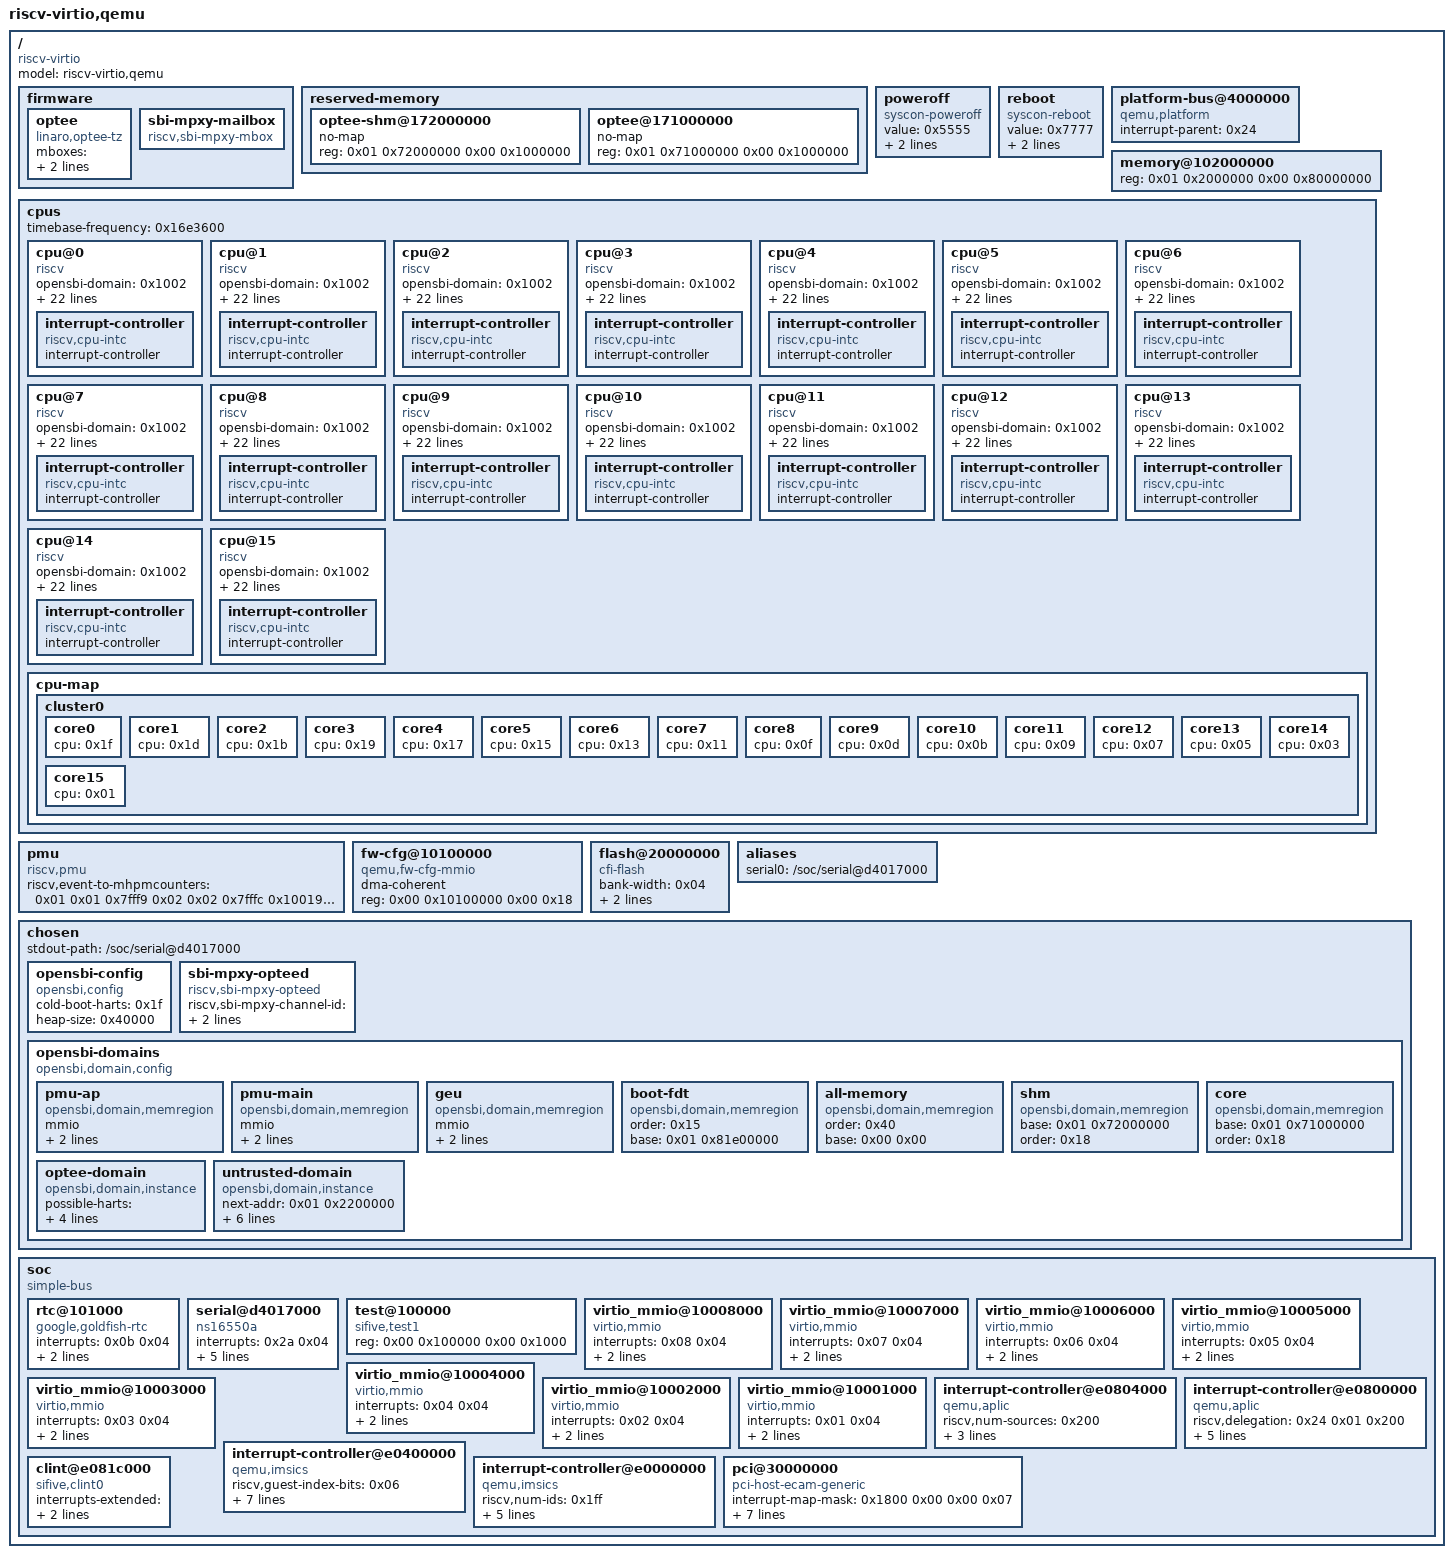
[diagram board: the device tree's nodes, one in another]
/dts-v1/;
/* QEMU jupiter2, 16 harts, 2 GiB. OP-TEE and Linux OpenSBI domains. */

/ {
	#address-cells = <0x02>;
	#size-cells = <0x02>;
	compatible = "riscv-virtio";
	model = "riscv-virtio,qemu";

	firmware {

		optee {
			mboxes = <0x1014 0x1000 0x02 0x1014 0x1001 0x02 0x1014 0x1002 0x02 0x1014 0x1003 0x02 0x1014 0x1004 0x02 0x1014 0x1005 0x02 0x1014 0x1006 0x02 0x1014 0x1007 0x02 0x1014 0x1008 0x02 0x1014 0x1009 0x02 0x1014 0x100a 0x02 0x1014 0x100b 0x02 0x1014 0x100c 0x02 0x1014 0x100d 0x02 0x1014 0x100e 0x02 0x1014 0x100f 0x02>;
			method = "smc";
			compatible = "linaro,optee-tz";
		};

		sbi-mpxy-mailbox {
			#mbox-cells = <0x02>;
			phandle = <0x1014>;
			compatible = "riscv,sbi-mpxy-mbox";
		};
	};

	reserved-memory {
		ranges;
		#size-cells = <0x02>;
		#address-cells = <0x02>;

		optee-shm@172000000 {
			no-map;
			reg = <0x01 0x72000000 0x00 0x1000000>;
		};

		optee@171000000 {
			no-map;
			reg = <0x01 0x71000000 0x00 0x1000000>;
		};
	};

	poweroff {
		value = <0x5555>;
		offset = <0x00>;
		regmap = <0x25>;
		compatible = "syscon-poweroff";
	};

	reboot {
		value = <0x7777>;
		offset = <0x00>;
		regmap = <0x25>;
		compatible = "syscon-reboot";
	};

	platform-bus@4000000 {
		interrupt-parent = <0x24>;
		ranges = <0x00 0x00 0x4000000 0x2000000>;
		#address-cells = <0x01>;
		#size-cells = <0x01>;
		compatible = "qemu,platform", "simple-bus";
	};

	memory@102000000 {
		device_type = "memory";
		reg = <0x01 0x2000000 0x00 0x80000000>;
	};

	cpus {
		#address-cells = <0x01>;
		#size-cells = <0x00>;
		timebase-frequency = <0x16e3600>;

		cpu@0 {
			opensbi-domain = <0x1002>;
			phandle = <0x1f>;
			device_type = "cpu";
			reg = <0x00>;
			status = "okay";
			compatible = "riscv";
			riscv,cbop-block-size = <0x40>;
			riscv,cboz-block-size = <0x40>;
			riscv,cbom-block-size = <0x40>;
			riscv,isa-extensions = "i", "m", "a", "f", "d", "c", "b", "v", "h", "zic64b", "zicbom", "zicbop", "zicboz", "ziccamoa", "ziccif", "zicclsm", "ziccrse", "zicond", "zicntr", "zicsr", "zifencei", "zihintntl", "zihintpause", "zihpm", "zimop", "zmmul", "za64rs", "zaamo", "zalrsc", "zawrs", "zfa", "zfhmin", "zca", "zcb", "zcd", "zcmop", "zba", "zbb", "zbs", "zkt", "zvbb", "zve32f", "zve32x", "zve64f", "zve64d", "zve64x", "zvfhmin", "zvkb", "zvkt", "sdtrig", "shcounterenw", "sha", "shgatpa", "shtvala", "shvsatpa", "shvstvala", "shvstvecd", "smaia", "smnpm", "smstateen", "ssaia", "ssccptr", "sscofpmf", "sscounterenw", "ssnpm", "ssstateen", "ssstrict", "sstc", "sstvala", "sstvecd", "ssu64xl", "supm", "svade", "svinval", "svnapot", "svpbmt";
			riscv,isa-base = "rv64i";
			riscv,isa = "rv64imafdcbvh_zic64b_zicbom_zicbop_zicboz_ziccamoa_ziccif_zicclsm_ziccrse_zicond_zicntr_zicsr_zifencei_zihintntl_zihintpause_zihpm_zimop_zmmul_za64rs_zaamo_zalrsc_zawrs_zfa_zfhmin_zca_zcb_zcd_zcmop_zba_zbb_zbs_zkt_zvbb_zve32f_zve32x_zve64f_zve64d_zve64x_zvfhmin_zvkb_zvkt_sdtrig_shcounterenw_sha_shgatpa_shtvala_shvsatpa_shvstvala_shvstvecd_smaia_smnpm_smstateen_ssaia_ssccptr_sscofpmf_sscounterenw_ssnpm_ssstateen_ssstrict_sstc_sstvala_sstvecd_ssu64xl_supm_svade_svinval_svnapot_svpbmt";
			mmu-type = "riscv,sv39";

			interrupt-controller {
				#interrupt-cells = <0x01>;
				interrupt-controller;
				compatible = "riscv,cpu-intc";
				phandle = <0x20>;
			};
		};

		cpu@1 {
			opensbi-domain = <0x1002>;
			phandle = <0x1d>;
			device_type = "cpu";
			reg = <0x01>;
			status = "okay";
			compatible = "riscv";
			riscv,cbop-block-size = <0x40>;
			riscv,cboz-block-size = <0x40>;
			riscv,cbom-block-size = <0x40>;
			riscv,isa-extensions = "i", "m", "a", "f", "d", "c", "b", "v", "h", "zic64b", "zicbom", "zicbop", "zicboz", "ziccamoa", "ziccif", "zicclsm", "ziccrse", "zicond", "zicntr", "zicsr", "zifencei", "zihintntl", "zihintpause", "zihpm", "zimop", "zmmul", "za64rs", "zaamo", "zalrsc", "zawrs", "zfa", "zfhmin", "zca", "zcb", "zcd", "zcmop", "zba", "zbb", "zbs", "zkt", "zvbb", "zve32f", "zve32x", "zve64f", "zve64d", "zve64x", "zvfhmin", "zvkb", "zvkt", "sdtrig", "shcounterenw", "sha", "shgatpa", "shtvala", "shvsatpa", "shvstvala", "shvstvecd", "smaia", "smnpm", "smstateen", "ssaia", "ssccptr", "sscofpmf", "sscounterenw", "ssnpm", "ssstateen", "ssstrict", "sstc", "sstvala", "sstvecd", "ssu64xl", "supm", "svade", "svinval", "svnapot", "svpbmt";
			riscv,isa-base = "rv64i";
			riscv,isa = "rv64imafdcbvh_zic64b_zicbom_zicbop_zicboz_ziccamoa_ziccif_zicclsm_ziccrse_zicond_zicntr_zicsr_zifencei_zihintntl_zihintpause_zihpm_zimop_zmmul_za64rs_zaamo_zalrsc_zawrs_zfa_zfhmin_zca_zcb_zcd_zcmop_zba_zbb_zbs_zkt_zvbb_zve32f_zve32x_zve64f_zve64d_zve64x_zvfhmin_zvkb_zvkt_sdtrig_shcounterenw_sha_shgatpa_shtvala_shvsatpa_shvstvala_shvstvecd_smaia_smnpm_smstateen_ssaia_ssccptr_sscofpmf_sscounterenw_ssnpm_ssstateen_ssstrict_sstc_sstvala_sstvecd_ssu64xl_supm_svade_svinval_svnapot_svpbmt";
			mmu-type = "riscv,sv39";

			interrupt-controller {
				#interrupt-cells = <0x01>;
				interrupt-controller;
				compatible = "riscv,cpu-intc";
				phandle = <0x1e>;
			};
		};

		cpu@2 {
			opensbi-domain = <0x1002>;
			phandle = <0x1b>;
			device_type = "cpu";
			reg = <0x02>;
			status = "okay";
			compatible = "riscv";
			riscv,cbop-block-size = <0x40>;
			riscv,cboz-block-size = <0x40>;
			riscv,cbom-block-size = <0x40>;
			riscv,isa-extensions = "i", "m", "a", "f", "d", "c", "b", "v", "h", "zic64b", "zicbom", "zicbop", "zicboz", "ziccamoa", "ziccif", "zicclsm", "ziccrse", "zicond", "zicntr", "zicsr", "zifencei", "zihintntl", "zihintpause", "zihpm", "zimop", "zmmul", "za64rs", "zaamo", "zalrsc", "zawrs", "zfa", "zfhmin", "zca", "zcb", "zcd", "zcmop", "zba", "zbb", "zbs", "zkt", "zvbb", "zve32f", "zve32x", "zve64f", "zve64d", "zve64x", "zvfhmin", "zvkb", "zvkt", "sdtrig", "shcounterenw", "sha", "shgatpa", "shtvala", "shvsatpa", "shvstvala", "shvstvecd", "smaia", "smnpm", "smstateen", "ssaia", "ssccptr", "sscofpmf", "sscounterenw", "ssnpm", "ssstateen", "ssstrict", "sstc", "sstvala", "sstvecd", "ssu64xl", "supm", "svade", "svinval", "svnapot", "svpbmt";
			riscv,isa-base = "rv64i";
			riscv,isa = "rv64imafdcbvh_zic64b_zicbom_zicbop_zicboz_ziccamoa_ziccif_zicclsm_ziccrse_zicond_zicntr_zicsr_zifencei_zihintntl_zihintpause_zihpm_zimop_zmmul_za64rs_zaamo_zalrsc_zawrs_zfa_zfhmin_zca_zcb_zcd_zcmop_zba_zbb_zbs_zkt_zvbb_zve32f_zve32x_zve64f_zve64d_zve64x_zvfhmin_zvkb_zvkt_sdtrig_shcounterenw_sha_shgatpa_shtvala_shvsatpa_shvstvala_shvstvecd_smaia_smnpm_smstateen_ssaia_ssccptr_sscofpmf_sscounterenw_ssnpm_ssstateen_ssstrict_sstc_sstvala_sstvecd_ssu64xl_supm_svade_svinval_svnapot_svpbmt";
			mmu-type = "riscv,sv39";

			interrupt-controller {
				#interrupt-cells = <0x01>;
				interrupt-controller;
				compatible = "riscv,cpu-intc";
				phandle = <0x1c>;
			};
		};

		cpu@3 {
			opensbi-domain = <0x1002>;
			phandle = <0x19>;
			device_type = "cpu";
			reg = <0x03>;
			status = "okay";
			compatible = "riscv";
			riscv,cbop-block-size = <0x40>;
			riscv,cboz-block-size = <0x40>;
			riscv,cbom-block-size = <0x40>;
			riscv,isa-extensions = "i", "m", "a", "f", "d", "c", "b", "v", "h", "zic64b", "zicbom", "zicbop", "zicboz", "ziccamoa", "ziccif", "zicclsm", "ziccrse", "zicond", "zicntr", "zicsr", "zifencei", "zihintntl", "zihintpause", "zihpm", "zimop", "zmmul", "za64rs", "zaamo", "zalrsc", "zawrs", "zfa", "zfhmin", "zca", "zcb", "zcd", "zcmop", "zba", "zbb", "zbs", "zkt", "zvbb", "zve32f", "zve32x", "zve64f", "zve64d", "zve64x", "zvfhmin", "zvkb", "zvkt", "sdtrig", "shcounterenw", "sha", "shgatpa", "shtvala", "shvsatpa", "shvstvala", "shvstvecd", "smaia", "smnpm", "smstateen", "ssaia", "ssccptr", "sscofpmf", "sscounterenw", "ssnpm", "ssstateen", "ssstrict", "sstc", "sstvala", "sstvecd", "ssu64xl", "supm", "svade", "svinval", "svnapot", "svpbmt";
			riscv,isa-base = "rv64i";
			riscv,isa = "rv64imafdcbvh_zic64b_zicbom_zicbop_zicboz_ziccamoa_ziccif_zicclsm_ziccrse_zicond_zicntr_zicsr_zifencei_zihintntl_zihintpause_zihpm_zimop_zmmul_za64rs_zaamo_zalrsc_zawrs_zfa_zfhmin_zca_zcb_zcd_zcmop_zba_zbb_zbs_zkt_zvbb_zve32f_zve32x_zve64f_zve64d_zve64x_zvfhmin_zvkb_zvkt_sdtrig_shcounterenw_sha_shgatpa_shtvala_shvsatpa_shvstvala_shvstvecd_smaia_smnpm_smstateen_ssaia_ssccptr_sscofpmf_sscounterenw_ssnpm_ssstateen_ssstrict_sstc_sstvala_sstvecd_ssu64xl_supm_svade_svinval_svnapot_svpbmt";
			mmu-type = "riscv,sv39";

			interrupt-controller {
				#interrupt-cells = <0x01>;
				interrupt-controller;
				compatible = "riscv,cpu-intc";
				phandle = <0x1a>;
			};
		};

		cpu@4 {
			opensbi-domain = <0x1002>;
			phandle = <0x17>;
			device_type = "cpu";
			reg = <0x04>;
			status = "okay";
			compatible = "riscv";
			riscv,cbop-block-size = <0x40>;
			riscv,cboz-block-size = <0x40>;
			riscv,cbom-block-size = <0x40>;
			riscv,isa-extensions = "i", "m", "a", "f", "d", "c", "b", "v", "h", "zic64b", "zicbom", "zicbop", "zicboz", "ziccamoa", "ziccif", "zicclsm", "ziccrse", "zicond", "zicntr", "zicsr", "zifencei", "zihintntl", "zihintpause", "zihpm", "zimop", "zmmul", "za64rs", "zaamo", "zalrsc", "zawrs", "zfa", "zfhmin", "zca", "zcb", "zcd", "zcmop", "zba", "zbb", "zbs", "zkt", "zvbb", "zve32f", "zve32x", "zve64f", "zve64d", "zve64x", "zvfhmin", "zvkb", "zvkt", "sdtrig", "shcounterenw", "sha", "shgatpa", "shtvala", "shvsatpa", "shvstvala", "shvstvecd", "smaia", "smnpm", "smstateen", "ssaia", "ssccptr", "sscofpmf", "sscounterenw", "ssnpm", "ssstateen", "ssstrict", "sstc", "sstvala", "sstvecd", "ssu64xl", "supm", "svade", "svinval", "svnapot", "svpbmt";
			riscv,isa-base = "rv64i";
			riscv,isa = "rv64imafdcbvh_zic64b_zicbom_zicbop_zicboz_ziccamoa_ziccif_zicclsm_ziccrse_zicond_zicntr_zicsr_zifencei_zihintntl_zihintpause_zihpm_zimop_zmmul_za64rs_zaamo_zalrsc_zawrs_zfa_zfhmin_zca_zcb_zcd_zcmop_zba_zbb_zbs_zkt_zvbb_zve32f_zve32x_zve64f_zve64d_zve64x_zvfhmin_zvkb_zvkt_sdtrig_shcounterenw_sha_shgatpa_shtvala_shvsatpa_shvstvala_shvstvecd_smaia_smnpm_smstateen_ssaia_ssccptr_sscofpmf_sscounterenw_ssnpm_ssstateen_ssstrict_sstc_sstvala_sstvecd_ssu64xl_supm_svade_svinval_svnapot_svpbmt";
			mmu-type = "riscv,sv39";

			interrupt-controller {
				#interrupt-cells = <0x01>;
				interrupt-controller;
				compatible = "riscv,cpu-intc";
				phandle = <0x18>;
			};
		};

		cpu@5 {
			opensbi-domain = <0x1002>;
			phandle = <0x15>;
			device_type = "cpu";
			reg = <0x05>;
			status = "okay";
			compatible = "riscv";
			riscv,cbop-block-size = <0x40>;
			riscv,cboz-block-size = <0x40>;
			riscv,cbom-block-size = <0x40>;
			riscv,isa-extensions = "i", "m", "a", "f", "d", "c", "b", "v", "h", "zic64b", "zicbom", "zicbop", "zicboz", "ziccamoa", "ziccif", "zicclsm", "ziccrse", "zicond", "zicntr", "zicsr", "zifencei", "zihintntl", "zihintpause", "zihpm", "zimop", "zmmul", "za64rs", "zaamo", "zalrsc", "zawrs", "zfa", "zfhmin", "zca", "zcb", "zcd", "zcmop", "zba", "zbb", "zbs", "zkt", "zvbb", "zve32f", "zve32x", "zve64f", "zve64d", "zve64x", "zvfhmin", "zvkb", "zvkt", "sdtrig", "shcounterenw", "sha", "shgatpa", "shtvala", "shvsatpa", "shvstvala", "shvstvecd", "smaia", "smnpm", "smstateen", "ssaia", "ssccptr", "sscofpmf", "sscounterenw", "ssnpm", "ssstateen", "ssstrict", "sstc", "sstvala", "sstvecd", "ssu64xl", "supm", "svade", "svinval", "svnapot", "svpbmt";
			riscv,isa-base = "rv64i";
			riscv,isa = "rv64imafdcbvh_zic64b_zicbom_zicbop_zicboz_ziccamoa_ziccif_zicclsm_ziccrse_zicond_zicntr_zicsr_zifencei_zihintntl_zihintpause_zihpm_zimop_zmmul_za64rs_zaamo_zalrsc_zawrs_zfa_zfhmin_zca_zcb_zcd_zcmop_zba_zbb_zbs_zkt_zvbb_zve32f_zve32x_zve64f_zve64d_zve64x_zvfhmin_zvkb_zvkt_sdtrig_shcounterenw_sha_shgatpa_shtvala_shvsatpa_shvstvala_shvstvecd_smaia_smnpm_smstateen_ssaia_ssccptr_sscofpmf_sscounterenw_ssnpm_ssstateen_ssstrict_sstc_sstvala_sstvecd_ssu64xl_supm_svade_svinval_svnapot_svpbmt";
			mmu-type = "riscv,sv39";

			interrupt-controller {
				#interrupt-cells = <0x01>;
				interrupt-controller;
				compatible = "riscv,cpu-intc";
				phandle = <0x16>;
			};
		};

		cpu@6 {
			opensbi-domain = <0x1002>;
			phandle = <0x13>;
			device_type = "cpu";
			reg = <0x06>;
			status = "okay";
			compatible = "riscv";
			riscv,cbop-block-size = <0x40>;
			riscv,cboz-block-size = <0x40>;
			riscv,cbom-block-size = <0x40>;
			riscv,isa-extensions = "i", "m", "a", "f", "d", "c", "b", "v", "h", "zic64b", "zicbom", "zicbop", "zicboz", "ziccamoa", "ziccif", "zicclsm", "ziccrse", "zicond", "zicntr", "zicsr", "zifencei", "zihintntl", "zihintpause", "zihpm", "zimop", "zmmul", "za64rs", "zaamo", "zalrsc", "zawrs", "zfa", "zfhmin", "zca", "zcb", "zcd", "zcmop", "zba", "zbb", "zbs", "zkt", "zvbb", "zve32f", "zve32x", "zve64f", "zve64d", "zve64x", "zvfhmin", "zvkb", "zvkt", "sdtrig", "shcounterenw", "sha", "shgatpa", "shtvala", "shvsatpa", "shvstvala", "shvstvecd", "smaia", "smnpm", "smstateen", "ssaia", "ssccptr", "sscofpmf", "sscounterenw", "ssnpm", "ssstateen", "ssstrict", "sstc", "sstvala", "sstvecd", "ssu64xl", "supm", "svade", "svinval", "svnapot", "svpbmt";
			riscv,isa-base = "rv64i";
			riscv,isa = "rv64imafdcbvh_zic64b_zicbom_zicbop_zicboz_ziccamoa_ziccif_zicclsm_ziccrse_zicond_zicntr_zicsr_zifencei_zihintntl_zihintpause_zihpm_zimop_zmmul_za64rs_zaamo_zalrsc_zawrs_zfa_zfhmin_zca_zcb_zcd_zcmop_zba_zbb_zbs_zkt_zvbb_zve32f_zve32x_zve64f_zve64d_zve64x_zvfhmin_zvkb_zvkt_sdtrig_shcounterenw_sha_shgatpa_shtvala_shvsatpa_shvstvala_shvstvecd_smaia_smnpm_smstateen_ssaia_ssccptr_sscofpmf_sscounterenw_ssnpm_ssstateen_ssstrict_sstc_sstvala_sstvecd_ssu64xl_supm_svade_svinval_svnapot_svpbmt";
			mmu-type = "riscv,sv39";

			interrupt-controller {
				#interrupt-cells = <0x01>;
				interrupt-controller;
				compatible = "riscv,cpu-intc";
				phandle = <0x14>;
			};
		};

		cpu@7 {
			opensbi-domain = <0x1002>;
			phandle = <0x11>;
			device_type = "cpu";
			reg = <0x07>;
			status = "okay";
			compatible = "riscv";
			riscv,cbop-block-size = <0x40>;
			riscv,cboz-block-size = <0x40>;
			riscv,cbom-block-size = <0x40>;
			riscv,isa-extensions = "i", "m", "a", "f", "d", "c", "b", "v", "h", "zic64b", "zicbom", "zicbop", "zicboz", "ziccamoa", "ziccif", "zicclsm", "ziccrse", "zicond", "zicntr", "zicsr", "zifencei", "zihintntl", "zihintpause", "zihpm", "zimop", "zmmul", "za64rs", "zaamo", "zalrsc", "zawrs", "zfa", "zfhmin", "zca", "zcb", "zcd", "zcmop", "zba", "zbb", "zbs", "zkt", "zvbb", "zve32f", "zve32x", "zve64f", "zve64d", "zve64x", "zvfhmin", "zvkb", "zvkt", "sdtrig", "shcounterenw", "sha", "shgatpa", "shtvala", "shvsatpa", "shvstvala", "shvstvecd", "smaia", "smnpm", "smstateen", "ssaia", "ssccptr", "sscofpmf", "sscounterenw", "ssnpm", "ssstateen", "ssstrict", "sstc", "sstvala", "sstvecd", "ssu64xl", "supm", "svade", "svinval", "svnapot", "svpbmt";
			riscv,isa-base = "rv64i";
			riscv,isa = "rv64imafdcbvh_zic64b_zicbom_zicbop_zicboz_ziccamoa_ziccif_zicclsm_ziccrse_zicond_zicntr_zicsr_zifencei_zihintntl_zihintpause_zihpm_zimop_zmmul_za64rs_zaamo_zalrsc_zawrs_zfa_zfhmin_zca_zcb_zcd_zcmop_zba_zbb_zbs_zkt_zvbb_zve32f_zve32x_zve64f_zve64d_zve64x_zvfhmin_zvkb_zvkt_sdtrig_shcounterenw_sha_shgatpa_shtvala_shvsatpa_shvstvala_shvstvecd_smaia_smnpm_smstateen_ssaia_ssccptr_sscofpmf_sscounterenw_ssnpm_ssstateen_ssstrict_sstc_sstvala_sstvecd_ssu64xl_supm_svade_svinval_svnapot_svpbmt";
			mmu-type = "riscv,sv39";

			interrupt-controller {
				#interrupt-cells = <0x01>;
				interrupt-controller;
				compatible = "riscv,cpu-intc";
				phandle = <0x12>;
			};
		};

		cpu@8 {
			opensbi-domain = <0x1002>;
			phandle = <0x0f>;
			device_type = "cpu";
			reg = <0x08>;
			status = "okay";
			compatible = "riscv";
			riscv,cbop-block-size = <0x40>;
			riscv,cboz-block-size = <0x40>;
			riscv,cbom-block-size = <0x40>;
			riscv,isa-extensions = "i", "m", "a", "f", "d", "c", "b", "v", "h", "zic64b", "zicbom", "zicbop", "zicboz", "ziccamoa", "ziccif", "zicclsm", "ziccrse", "zicond", "zicntr", "zicsr", "zifencei", "zihintntl", "zihintpause", "zihpm", "zimop", "zmmul", "za64rs", "zaamo", "zalrsc", "zawrs", "zfa", "zfhmin", "zca", "zcb", "zcd", "zcmop", "zba", "zbb", "zbs", "zkt", "zvbb", "zve32f", "zve32x", "zve64f", "zve64d", "zve64x", "zvfhmin", "zvkb", "zvkt", "sdtrig", "shcounterenw", "sha", "shgatpa", "shtvala", "shvsatpa", "shvstvala", "shvstvecd", "smaia", "smnpm", "smstateen", "ssaia", "ssccptr", "sscofpmf", "sscounterenw", "ssnpm", "ssstateen", "ssstrict", "sstc", "sstvala", "sstvecd", "ssu64xl", "supm", "svade", "svinval", "svnapot", "svpbmt";
			riscv,isa-base = "rv64i";
			riscv,isa = "rv64imafdcbvh_zic64b_zicbom_zicbop_zicboz_ziccamoa_ziccif_zicclsm_ziccrse_zicond_zicntr_zicsr_zifencei_zihintntl_zihintpause_zihpm_zimop_zmmul_za64rs_zaamo_zalrsc_zawrs_zfa_zfhmin_zca_zcb_zcd_zcmop_zba_zbb_zbs_zkt_zvbb_zve32f_zve32x_zve64f_zve64d_zve64x_zvfhmin_zvkb_zvkt_sdtrig_shcounterenw_sha_shgatpa_shtvala_shvsatpa_shvstvala_shvstvecd_smaia_smnpm_smstateen_ssaia_ssccptr_sscofpmf_sscounterenw_ssnpm_ssstateen_ssstrict_sstc_sstvala_sstvecd_ssu64xl_supm_svade_svinval_svnapot_svpbmt";
			mmu-type = "riscv,sv39";

			interrupt-controller {
				#interrupt-cells = <0x01>;
				interrupt-controller;
				compatible = "riscv,cpu-intc";
				phandle = <0x10>;
			};
		};

		cpu@9 {
			opensbi-domain = <0x1002>;
			phandle = <0x0d>;
			device_type = "cpu";
			reg = <0x09>;
			status = "okay";
			compatible = "riscv";
			riscv,cbop-block-size = <0x40>;
			riscv,cboz-block-size = <0x40>;
			riscv,cbom-block-size = <0x40>;
			riscv,isa-extensions = "i", "m", "a", "f", "d", "c", "b", "v", "h", "zic64b", "zicbom", "zicbop", "zicboz", "ziccamoa", "ziccif", "zicclsm", "ziccrse", "zicond", "zicntr", "zicsr", "zifencei", "zihintntl", "zihintpause", "zihpm", "zimop", "zmmul", "za64rs", "zaamo", "zalrsc", "zawrs", "zfa", "zfhmin", "zca", "zcb", "zcd", "zcmop", "zba", "zbb", "zbs", "zkt", "zvbb", "zve32f", "zve32x", "zve64f", "zve64d", "zve64x", "zvfhmin", "zvkb", "zvkt", "sdtrig", "shcounterenw", "sha", "shgatpa", "shtvala", "shvsatpa", "shvstvala", "shvstvecd", "smaia", "smnpm", "smstateen", "ssaia", "ssccptr", "sscofpmf", "sscounterenw", "ssnpm", "ssstateen", "ssstrict", "sstc", "sstvala", "sstvecd", "ssu64xl", "supm", "svade", "svinval", "svnapot", "svpbmt";
			riscv,isa-base = "rv64i";
			riscv,isa = "rv64imafdcbvh_zic64b_zicbom_zicbop_zicboz_ziccamoa_ziccif_zicclsm_ziccrse_zicond_zicntr_zicsr_zifencei_zihintntl_zihintpause_zihpm_zimop_zmmul_za64rs_zaamo_zalrsc_zawrs_zfa_zfhmin_zca_zcb_zcd_zcmop_zba_zbb_zbs_zkt_zvbb_zve32f_zve32x_zve64f_zve64d_zve64x_zvfhmin_zvkb_zvkt_sdtrig_shcounterenw_sha_shgatpa_shtvala_shvsatpa_shvstvala_shvstvecd_smaia_smnpm_smstateen_ssaia_ssccptr_sscofpmf_sscounterenw_ssnpm_ssstateen_ssstrict_sstc_sstvala_sstvecd_ssu64xl_supm_svade_svinval_svnapot_svpbmt";
			mmu-type = "riscv,sv39";

			interrupt-controller {
				#interrupt-cells = <0x01>;
				interrupt-controller;
				compatible = "riscv,cpu-intc";
				phandle = <0x0e>;
			};
		};

		cpu@10 {
			opensbi-domain = <0x1002>;
			phandle = <0x0b>;
			device_type = "cpu";
			reg = <0x0a>;
			status = "okay";
			compatible = "riscv";
			riscv,cbop-block-size = <0x40>;
			riscv,cboz-block-size = <0x40>;
			riscv,cbom-block-size = <0x40>;
			riscv,isa-extensions = "i", "m", "a", "f", "d", "c", "b", "v", "h", "zic64b", "zicbom", "zicbop", "zicboz", "ziccamoa", "ziccif", "zicclsm", "ziccrse", "zicond", "zicntr", "zicsr", "zifencei", "zihintntl", "zihintpause", "zihpm", "zimop", "zmmul", "za64rs", "zaamo", "zalrsc", "zawrs", "zfa", "zfhmin", "zca", "zcb", "zcd", "zcmop", "zba", "zbb", "zbs", "zkt", "zvbb", "zve32f", "zve32x", "zve64f", "zve64d", "zve64x", "zvfhmin", "zvkb", "zvkt", "sdtrig", "shcounterenw", "sha", "shgatpa", "shtvala", "shvsatpa", "shvstvala", "shvstvecd", "smaia", "smnpm", "smstateen", "ssaia", "ssccptr", "sscofpmf", "sscounterenw", "ssnpm", "ssstateen", "ssstrict", "sstc", "sstvala", "sstvecd", "ssu64xl", "supm", "svade", "svinval", "svnapot", "svpbmt";
			riscv,isa-base = "rv64i";
			riscv,isa = "rv64imafdcbvh_zic64b_zicbom_zicbop_zicboz_ziccamoa_ziccif_zicclsm_ziccrse_zicond_zicntr_zicsr_zifencei_zihintntl_zihintpause_zihpm_zimop_zmmul_za64rs_zaamo_zalrsc_zawrs_zfa_zfhmin_zca_zcb_zcd_zcmop_zba_zbb_zbs_zkt_zvbb_zve32f_zve32x_zve64f_zve64d_zve64x_zvfhmin_zvkb_zvkt_sdtrig_shcounterenw_sha_shgatpa_shtvala_shvsatpa_shvstvala_shvstvecd_smaia_smnpm_smstateen_ssaia_ssccptr_sscofpmf_sscounterenw_ssnpm_ssstateen_ssstrict_sstc_sstvala_sstvecd_ssu64xl_supm_svade_svinval_svnapot_svpbmt";
			mmu-type = "riscv,sv39";

			interrupt-controller {
				#interrupt-cells = <0x01>;
				interrupt-controller;
				compatible = "riscv,cpu-intc";
				phandle = <0x0c>;
			};
		};

		cpu@11 {
			opensbi-domain = <0x1002>;
			phandle = <0x09>;
			device_type = "cpu";
			reg = <0x0b>;
			status = "okay";
			compatible = "riscv";
			riscv,cbop-block-size = <0x40>;
			riscv,cboz-block-size = <0x40>;
			riscv,cbom-block-size = <0x40>;
			riscv,isa-extensions = "i", "m", "a", "f", "d", "c", "b", "v", "h", "zic64b", "zicbom", "zicbop", "zicboz", "ziccamoa", "ziccif", "zicclsm", "ziccrse", "zicond", "zicntr", "zicsr", "zifencei", "zihintntl", "zihintpause", "zihpm", "zimop", "zmmul", "za64rs", "zaamo", "zalrsc", "zawrs", "zfa", "zfhmin", "zca", "zcb", "zcd", "zcmop", "zba", "zbb", "zbs", "zkt", "zvbb", "zve32f", "zve32x", "zve64f", "zve64d", "zve64x", "zvfhmin", "zvkb", "zvkt", "sdtrig", "shcounterenw", "sha", "shgatpa", "shtvala", "shvsatpa", "shvstvala", "shvstvecd", "smaia", "smnpm", "smstateen", "ssaia", "ssccptr", "sscofpmf", "sscounterenw", "ssnpm", "ssstateen", "ssstrict", "sstc", "sstvala", "sstvecd", "ssu64xl", "supm", "svade", "svinval", "svnapot", "svpbmt";
			riscv,isa-base = "rv64i";
			riscv,isa = "rv64imafdcbvh_zic64b_zicbom_zicbop_zicboz_ziccamoa_ziccif_zicclsm_ziccrse_zicond_zicntr_zicsr_zifencei_zihintntl_zihintpause_zihpm_zimop_zmmul_za64rs_zaamo_zalrsc_zawrs_zfa_zfhmin_zca_zcb_zcd_zcmop_zba_zbb_zbs_zkt_zvbb_zve32f_zve32x_zve64f_zve64d_zve64x_zvfhmin_zvkb_zvkt_sdtrig_shcounterenw_sha_shgatpa_shtvala_shvsatpa_shvstvala_shvstvecd_smaia_smnpm_smstateen_ssaia_ssccptr_sscofpmf_sscounterenw_ssnpm_ssstateen_ssstrict_sstc_sstvala_sstvecd_ssu64xl_supm_svade_svinval_svnapot_svpbmt";
			mmu-type = "riscv,sv39";

			interrupt-controller {
				#interrupt-cells = <0x01>;
				interrupt-controller;
				compatible = "riscv,cpu-intc";
				phandle = <0x0a>;
			};
		};

		cpu@12 {
			opensbi-domain = <0x1002>;
			phandle = <0x07>;
			device_type = "cpu";
			reg = <0x0c>;
			status = "okay";
			compatible = "riscv";
			riscv,cbop-block-size = <0x40>;
			riscv,cboz-block-size = <0x40>;
			riscv,cbom-block-size = <0x40>;
			riscv,isa-extensions = "i", "m", "a", "f", "d", "c", "b", "v", "h", "zic64b", "zicbom", "zicbop", "zicboz", "ziccamoa", "ziccif", "zicclsm", "ziccrse", "zicond", "zicntr", "zicsr", "zifencei", "zihintntl", "zihintpause", "zihpm", "zimop", "zmmul", "za64rs", "zaamo", "zalrsc", "zawrs", "zfa", "zfhmin", "zca", "zcb", "zcd", "zcmop", "zba", "zbb", "zbs", "zkt", "zvbb", "zve32f", "zve32x", "zve64f", "zve64d", "zve64x", "zvfhmin", "zvkb", "zvkt", "sdtrig", "shcounterenw", "sha", "shgatpa", "shtvala", "shvsatpa", "shvstvala", "shvstvecd", "smaia", "smnpm", "smstateen", "ssaia", "ssccptr", "sscofpmf", "sscounterenw", "ssnpm", "ssstateen", "ssstrict", "sstc", "sstvala", "sstvecd", "ssu64xl", "supm", "svade", "svinval", "svnapot", "svpbmt";
			riscv,isa-base = "rv64i";
			riscv,isa = "rv64imafdcbvh_zic64b_zicbom_zicbop_zicboz_ziccamoa_ziccif_zicclsm_ziccrse_zicond_zicntr_zicsr_zifencei_zihintntl_zihintpause_zihpm_zimop_zmmul_za64rs_zaamo_zalrsc_zawrs_zfa_zfhmin_zca_zcb_zcd_zcmop_zba_zbb_zbs_zkt_zvbb_zve32f_zve32x_zve64f_zve64d_zve64x_zvfhmin_zvkb_zvkt_sdtrig_shcounterenw_sha_shgatpa_shtvala_shvsatpa_shvstvala_shvstvecd_smaia_smnpm_smstateen_ssaia_ssccptr_sscofpmf_sscounterenw_ssnpm_ssstateen_ssstrict_sstc_sstvala_sstvecd_ssu64xl_supm_svade_svinval_svnapot_svpbmt";
			mmu-type = "riscv,sv39";

			interrupt-controller {
				#interrupt-cells = <0x01>;
				interrupt-controller;
				compatible = "riscv,cpu-intc";
				phandle = <0x08>;
			};
		};

		cpu@13 {
			opensbi-domain = <0x1002>;
			phandle = <0x05>;
			device_type = "cpu";
			reg = <0x0d>;
			status = "okay";
			compatible = "riscv";
			riscv,cbop-block-size = <0x40>;
			riscv,cboz-block-size = <0x40>;
			riscv,cbom-block-size = <0x40>;
			riscv,isa-extensions = "i", "m", "a", "f", "d", "c", "b", "v", "h", "zic64b", "zicbom", "zicbop", "zicboz", "ziccamoa", "ziccif", "zicclsm", "ziccrse", "zicond", "zicntr", "zicsr", "zifencei", "zihintntl", "zihintpause", "zihpm", "zimop", "zmmul", "za64rs", "zaamo", "zalrsc", "zawrs", "zfa", "zfhmin", "zca", "zcb", "zcd", "zcmop", "zba", "zbb", "zbs", "zkt", "zvbb", "zve32f", "zve32x", "zve64f", "zve64d", "zve64x", "zvfhmin", "zvkb", "zvkt", "sdtrig", "shcounterenw", "sha", "shgatpa", "shtvala", "shvsatpa", "shvstvala", "shvstvecd", "smaia", "smnpm", "smstateen", "ssaia", "ssccptr", "sscofpmf", "sscounterenw", "ssnpm", "ssstateen", "ssstrict", "sstc", "sstvala", "sstvecd", "ssu64xl", "supm", "svade", "svinval", "svnapot", "svpbmt";
			riscv,isa-base = "rv64i";
			riscv,isa = "rv64imafdcbvh_zic64b_zicbom_zicbop_zicboz_ziccamoa_ziccif_zicclsm_ziccrse_zicond_zicntr_zicsr_zifencei_zihintntl_zihintpause_zihpm_zimop_zmmul_za64rs_zaamo_zalrsc_zawrs_zfa_zfhmin_zca_zcb_zcd_zcmop_zba_zbb_zbs_zkt_zvbb_zve32f_zve32x_zve64f_zve64d_zve64x_zvfhmin_zvkb_zvkt_sdtrig_shcounterenw_sha_shgatpa_shtvala_shvsatpa_shvstvala_shvstvecd_smaia_smnpm_smstateen_ssaia_ssccptr_sscofpmf_sscounterenw_ssnpm_ssstateen_ssstrict_sstc_sstvala_sstvecd_ssu64xl_supm_svade_svinval_svnapot_svpbmt";
			mmu-type = "riscv,sv39";

			interrupt-controller {
				#interrupt-cells = <0x01>;
				interrupt-controller;
				compatible = "riscv,cpu-intc";
				phandle = <0x06>;
			};
		};

		cpu@14 {
			opensbi-domain = <0x1002>;
			phandle = <0x03>;
			device_type = "cpu";
			reg = <0x0e>;
			status = "okay";
			compatible = "riscv";
			riscv,cbop-block-size = <0x40>;
			riscv,cboz-block-size = <0x40>;
			riscv,cbom-block-size = <0x40>;
			riscv,isa-extensions = "i", "m", "a", "f", "d", "c", "b", "v", "h", "zic64b", "zicbom", "zicbop", "zicboz", "ziccamoa", "ziccif", "zicclsm", "ziccrse", "zicond", "zicntr", "zicsr", "zifencei", "zihintntl", "zihintpause", "zihpm", "zimop", "zmmul", "za64rs", "zaamo", "zalrsc", "zawrs", "zfa", "zfhmin", "zca", "zcb", "zcd", "zcmop", "zba", "zbb", "zbs", "zkt", "zvbb", "zve32f", "zve32x", "zve64f", "zve64d", "zve64x", "zvfhmin", "zvkb", "zvkt", "sdtrig", "shcounterenw", "sha", "shgatpa", "shtvala", "shvsatpa", "shvstvala", "shvstvecd", "smaia", "smnpm", "smstateen", "ssaia", "ssccptr", "sscofpmf", "sscounterenw", "ssnpm", "ssstateen", "ssstrict", "sstc", "sstvala", "sstvecd", "ssu64xl", "supm", "svade", "svinval", "svnapot", "svpbmt";
			riscv,isa-base = "rv64i";
			riscv,isa = "rv64imafdcbvh_zic64b_zicbom_zicbop_zicboz_ziccamoa_ziccif_zicclsm_ziccrse_zicond_zicntr_zicsr_zifencei_zihintntl_zihintpause_zihpm_zimop_zmmul_za64rs_zaamo_zalrsc_zawrs_zfa_zfhmin_zca_zcb_zcd_zcmop_zba_zbb_zbs_zkt_zvbb_zve32f_zve32x_zve64f_zve64d_zve64x_zvfhmin_zvkb_zvkt_sdtrig_shcounterenw_sha_shgatpa_shtvala_shvsatpa_shvstvala_shvstvecd_smaia_smnpm_smstateen_ssaia_ssccptr_sscofpmf_sscounterenw_ssnpm_ssstateen_ssstrict_sstc_sstvala_sstvecd_ssu64xl_supm_svade_svinval_svnapot_svpbmt";
			mmu-type = "riscv,sv39";

			interrupt-controller {
				#interrupt-cells = <0x01>;
				interrupt-controller;
				compatible = "riscv,cpu-intc";
				phandle = <0x04>;
			};
		};

		cpu@15 {
			opensbi-domain = <0x1002>;
			phandle = <0x01>;
			device_type = "cpu";
			reg = <0x0f>;
			status = "okay";
			compatible = "riscv";
			riscv,cbop-block-size = <0x40>;
			riscv,cboz-block-size = <0x40>;
			riscv,cbom-block-size = <0x40>;
			riscv,isa-extensions = "i", "m", "a", "f", "d", "c", "b", "v", "h", "zic64b", "zicbom", "zicbop", "zicboz", "ziccamoa", "ziccif", "zicclsm", "ziccrse", "zicond", "zicntr", "zicsr", "zifencei", "zihintntl", "zihintpause", "zihpm", "zimop", "zmmul", "za64rs", "zaamo", "zalrsc", "zawrs", "zfa", "zfhmin", "zca", "zcb", "zcd", "zcmop", "zba", "zbb", "zbs", "zkt", "zvbb", "zve32f", "zve32x", "zve64f", "zve64d", "zve64x", "zvfhmin", "zvkb", "zvkt", "sdtrig", "shcounterenw", "sha", "shgatpa", "shtvala", "shvsatpa", "shvstvala", "shvstvecd", "smaia", "smnpm", "smstateen", "ssaia", "ssccptr", "sscofpmf", "sscounterenw", "ssnpm", "ssstateen", "ssstrict", "sstc", "sstvala", "sstvecd", "ssu64xl", "supm", "svade", "svinval", "svnapot", "svpbmt";
			riscv,isa-base = "rv64i";
			riscv,isa = "rv64imafdcbvh_zic64b_zicbom_zicbop_zicboz_ziccamoa_ziccif_zicclsm_ziccrse_zicond_zicntr_zicsr_zifencei_zihintntl_zihintpause_zihpm_zimop_zmmul_za64rs_zaamo_zalrsc_zawrs_zfa_zfhmin_zca_zcb_zcd_zcmop_zba_zbb_zbs_zkt_zvbb_zve32f_zve32x_zve64f_zve64d_zve64x_zvfhmin_zvkb_zvkt_sdtrig_shcounterenw_sha_shgatpa_shtvala_shvsatpa_shvstvala_shvstvecd_smaia_smnpm_smstateen_ssaia_ssccptr_sscofpmf_sscounterenw_ssnpm_ssstateen_ssstrict_sstc_sstvala_sstvecd_ssu64xl_supm_svade_svinval_svnapot_svpbmt";
			mmu-type = "riscv,sv39";

			interrupt-controller {
				#interrupt-cells = <0x01>;
				interrupt-controller;
				compatible = "riscv,cpu-intc";
				phandle = <0x02>;
			};
		};

		cpu-map {

			cluster0 {

				core0 {
					cpu = <0x1f>;
				};

				core1 {
					cpu = <0x1d>;
				};

				core2 {
					cpu = <0x1b>;
				};

				core3 {
					cpu = <0x19>;
				};

				core4 {
					cpu = <0x17>;
				};

				core5 {
					cpu = <0x15>;
				};

				core6 {
					cpu = <0x13>;
				};

				core7 {
					cpu = <0x11>;
				};

				core8 {
					cpu = <0x0f>;
				};

				core9 {
					cpu = <0x0d>;
				};

				core10 {
					cpu = <0x0b>;
				};

				core11 {
					cpu = <0x09>;
				};

				core12 {
					cpu = <0x07>;
				};

				core13 {
					cpu = <0x05>;
				};

				core14 {
					cpu = <0x03>;
				};

				core15 {
					cpu = <0x01>;
				};
			};
		};
	};

	pmu {
		riscv,event-to-mhpmcounters = <0x01 0x01 0x7fff9 0x02 0x02 0x7fffc 0x10019 0x10019 0x7fff8 0x1001b 0x1001b 0x7fff8 0x10021 0x10021 0x7fff8>;
		compatible = "riscv,pmu";
	};

	fw-cfg@10100000 {
		dma-coherent;
		reg = <0x00 0x10100000 0x00 0x18>;
		compatible = "qemu,fw-cfg-mmio";
	};

	flash@20000000 {
		bank-width = <0x04>;
		reg = <0x00 0x20000000 0x00 0x2000000 0x00 0x22000000 0x00 0x2000000>;
		compatible = "cfi-flash";
	};

	aliases {
		serial0 = "/soc/serial@d4017000";
	};

	chosen {
		stdout-path = "/soc/serial@d4017000";

		opensbi-config {
			cold-boot-harts = <0x1f>;
			heap-size = <0x40000>;
			compatible = "opensbi,config";
		};

		sbi-mpxy-opteed {
			riscv,sbi-mpxy-channel-id = <0x1000 0x1001 0x1002 0x1003 0x1004 0x1005 0x1006 0x1007 0x1008 0x1009 0x100a 0x100b 0x100c 0x100d 0x100e 0x100f>;
			opensbi-domain-instance = <0x1002>;
			compatible = "riscv,sbi-mpxy-opteed";
		};

		opensbi-domains {
			compatible = "opensbi,domain,config";

			pmu-ap {
				mmio;
				order = <0x0c>;
				base = <0x00 0xd4282000>;
				phandle = <0x1032>;
				compatible = "opensbi,domain,memregion";
			};

			pmu-main {
				mmio;
				order = <0x0e>;
				base = <0x00 0xd4050000>;
				phandle = <0x1031>;
				compatible = "opensbi,domain,memregion";
			};

			geu {
				mmio;
				order = <0x0a>;
				base = <0x00 0xf0702800>;
				phandle = <0x1030>;
				compatible = "opensbi,domain,memregion";
			};

			boot-fdt {
				order = <0x15>;
				base = <0x01 0x81e00000>;
				phandle = <0x1020>;
				compatible = "opensbi,domain,memregion";
			};

			all-memory {
				phandle = <0x1012>;
				order = <0x40>;
				base = <0x00 0x00>;
				compatible = "opensbi,domain,memregion";
			};

			shm {
				phandle = <0x1011>;
				base = <0x01 0x72000000>;
				order = <0x18>;
				compatible = "opensbi,domain,memregion";
			};

			core {
				phandle = <0x1010>;
				base = <0x01 0x71000000>;
				order = <0x18>;
				compatible = "opensbi,domain,memregion";
			};

			optee-domain {
				possible-harts = <0x1f 0x1d 0x1b 0x19 0x17 0x15 0x13 0x11 0x0f 0x0d 0x0b 0x09 0x07 0x05 0x03 0x01>;
				regions = <0x1010 0x38 0x1011 0x18 0x1020 0x18 0x1030 0x18 0x1031 0x18 0x1032 0x18>;
				next-addr = <0x01 0x71000000>;
				phandle = <0x1002>;
				compatible = "opensbi,domain,instance";
			};

			untrusted-domain {
				next-addr = <0x01 0x2200000>;
				boot-hart = <0x1f>;
				system-reset-allowed;
				possible-harts = <0x1f 0x1d 0x1b 0x19 0x17 0x15 0x13 0x11 0x0f 0x0d 0x0b 0x09 0x07 0x05 0x03 0x01>;
				phandle = <0x1013>;
				regions = <0x1010 0x00 0x1011 0x18 0x1012 0x38 0x1020 0x18 0x1030 0x00 0x1031 0x00 0x1032 0x00>;
				compatible = "opensbi,domain,instance";
			};
		};
	};

	soc {
		#address-cells = <0x02>;
		#size-cells = <0x02>;
		compatible = "simple-bus";
		ranges;

		rtc@101000 {
			interrupts = <0x0b 0x04>;
			interrupt-parent = <0x24>;
			reg = <0x00 0x101000 0x00 0x1000>;
			compatible = "google,goldfish-rtc";
		};

		serial@d4017000 {
			interrupts = <0x2a 0x04>;
			interrupt-parent = <0x24>;
			clock-frequency = "", "8@";
			reg = <0x00 0xd4017000 0x00 0x100>;
			reg-io-width = <0x04>;
			reg-shift = <0x02>;
			compatible = "ns16550a";
		};

		test@100000 {
			phandle = <0x25>;
			reg = <0x00 0x100000 0x00 0x1000>;
			compatible = "sifive,test1", "sifive,test0", "syscon";
		};

		virtio_mmio@10008000 {
			interrupts = <0x08 0x04>;
			interrupt-parent = <0x24>;
			reg = <0x00 0x10008000 0x00 0x1000>;
			compatible = "virtio,mmio";
		};

		virtio_mmio@10007000 {
			interrupts = <0x07 0x04>;
			interrupt-parent = <0x24>;
			reg = <0x00 0x10007000 0x00 0x1000>;
			compatible = "virtio,mmio";
		};

		virtio_mmio@10006000 {
			interrupts = <0x06 0x04>;
			interrupt-parent = <0x24>;
			reg = <0x00 0x10006000 0x00 0x1000>;
			compatible = "virtio,mmio";
		};

		virtio_mmio@10005000 {
			interrupts = <0x05 0x04>;
			interrupt-parent = <0x24>;
			reg = <0x00 0x10005000 0x00 0x1000>;
			compatible = "virtio,mmio";
		};

		virtio_mmio@10004000 {
			interrupts = <0x04 0x04>;
			interrupt-parent = <0x24>;
			reg = <0x00 0x10004000 0x00 0x1000>;
			compatible = "virtio,mmio";
		};

		virtio_mmio@10003000 {
			interrupts = <0x03 0x04>;
			interrupt-parent = <0x24>;
			reg = <0x00 0x10003000 0x00 0x1000>;
			compatible = "virtio,mmio";
		};

		virtio_mmio@10002000 {
			interrupts = <0x02 0x04>;
			interrupt-parent = <0x24>;
			reg = <0x00 0x10002000 0x00 0x1000>;
			compatible = "virtio,mmio";
		};

		virtio_mmio@10001000 {
			interrupts = <0x01 0x04>;
			interrupt-parent = <0x24>;
			reg = <0x00 0x10001000 0x00 0x1000>;
			compatible = "virtio,mmio";
		};

		interrupt-controller@e0804000 {
			phandle = <0x24>;
			riscv,num-sources = <0x200>;
			reg = <0x00 0xe0804000 0x00 0x4000>;
			msi-parent = <0x22>;
			interrupt-controller;
			#interrupt-cells = <0x02>;
			#address-cells = <0x00>;
			compatible = "qemu,aplic", "riscv,aplic";
		};

		interrupt-controller@e0800000 {
			phandle = <0x23>;
			riscv,delegation = <0x24 0x01 0x200>;
			riscv,children = <0x24>;
			riscv,num-sources = <0x200>;
			reg = <0x00 0xe0800000 0x00 0x4000>;
			msi-parent = <0x21>;
			interrupt-controller;
			#interrupt-cells = <0x02>;
			#address-cells = <0x00>;
			compatible = "qemu,aplic", "riscv,aplic";
		};

		interrupt-controller@e0400000 {
			phandle = <0x22>;
			riscv,guest-index-bits = <0x06>;
			riscv,num-guest-ids = <0x3f>;
			riscv,num-ids = <0x1ff>;
			reg = <0x00 0xe0400000 0x00 0x400000>;
			interrupts-extended = <0x20 0x09 0x1e 0x09 0x1c 0x09 0x1a 0x09 0x18 0x09 0x16 0x09 0x14 0x09 0x12 0x09 0x10 0x09 0x0e 0x09 0x0c 0x09 0x0a 0x09 0x08 0x09 0x06 0x09 0x04 0x09 0x02 0x09>;
			msi-controller;
			interrupt-controller;
			#interrupt-cells = <0x00>;
			compatible = "qemu,imsics", "riscv,imsics";
		};

		interrupt-controller@e0000000 {
			phandle = <0x21>;
			riscv,num-ids = <0x1ff>;
			reg = <0x00 0xe0000000 0x00 0x10000>;
			interrupts-extended = <0x20 0x0b 0x1e 0x0b 0x1c 0x0b 0x1a 0x0b 0x18 0x0b 0x16 0x0b 0x14 0x0b 0x12 0x0b 0x10 0x0b 0x0e 0x0b 0x0c 0x0b 0x0a 0x0b 0x08 0x0b 0x06 0x0b 0x04 0x0b 0x02 0x0b>;
			msi-controller;
			interrupt-controller;
			#interrupt-cells = <0x00>;
			compatible = "qemu,imsics", "riscv,imsics";
		};

		clint@e081c000 {
			interrupts-extended = <0x20 0x03 0x20 0x07 0x1e 0x03 0x1e 0x07 0x1c 0x03 0x1c 0x07 0x1a 0x03 0x1a 0x07 0x18 0x03 0x18 0x07 0x16 0x03 0x16 0x07 0x14 0x03 0x14 0x07 0x12 0x03 0x12 0x07 0x10 0x03 0x10 0x07 0x0e 0x03 0x0e 0x07 0x0c 0x03 0x0c 0x07 0x0a 0x03 0x0a 0x07 0x08 0x03 0x08 0x07 0x06 0x03 0x06 0x07 0x04 0x03 0x04 0x07 0x02 0x03 0x02 0x07>;
			reg = <0x00 0xe081c000 0x00 0x4000>;
			compatible = "sifive,clint0", "riscv,clint0";
		};

		pci@30000000 {
			interrupt-map-mask = <0x1800 0x00 0x00 0x07>;
			interrupt-map = <0x00 0x00 0x00 0x01 0x24 0x20 0x04 0x00 0x00 0x00 0x02 0x24 0x21 0x04 0x00 0x00 0x00 0x03 0x24 0x22 0x04 0x00 0x00 0x00 0x04 0x24 0x23 0x04 0x800 0x00 0x00 0x01 0x24 0x21 0x04 0x800 0x00 0x00 0x02 0x24 0x22 0x04 0x800 0x00 0x00 0x03 0x24 0x23 0x04 0x800 0x00 0x00 0x04 0x24 0x20 0x04 0x1000 0x00 0x00 0x01 0x24 0x22 0x04 0x1000 0x00 0x00 0x02 0x24 0x23 0x04 0x1000 0x00 0x00 0x03 0x24 0x20 0x04 0x1000 0x00 0x00 0x04 0x24 0x21 0x04 0x1800 0x00 0x00 0x01 0x24 0x23 0x04 0x1800 0x00 0x00 0x02 0x24 0x20 0x04 0x1800 0x00 0x00 0x03 0x24 0x21 0x04 0x1800 0x00 0x00 0x04 0x24 0x22 0x04>;
			ranges = <0x1000000 0x00 0x00 0x00 0x3000000 0x00 0x10000 0x2000000 0x00 0x40000000 0x00 0x40000000 0x00 0x40000000 0x3000000 0x04 0x00 0x04 0x00 0x04 0x00>;
			reg = <0x00 0x30000000 0x00 0x10000000>;
			msi-parent = <0x22>;
			dma-coherent;
			bus-range = <0x00 0xff>;
			linux,pci-domain = <0x00>;
			device_type = "pci";
			compatible = "pci-host-ecam-generic";
			#size-cells = <0x02>;
			#interrupt-cells = <0x01>;
			#address-cells = <0x03>;
		};
	};
};
